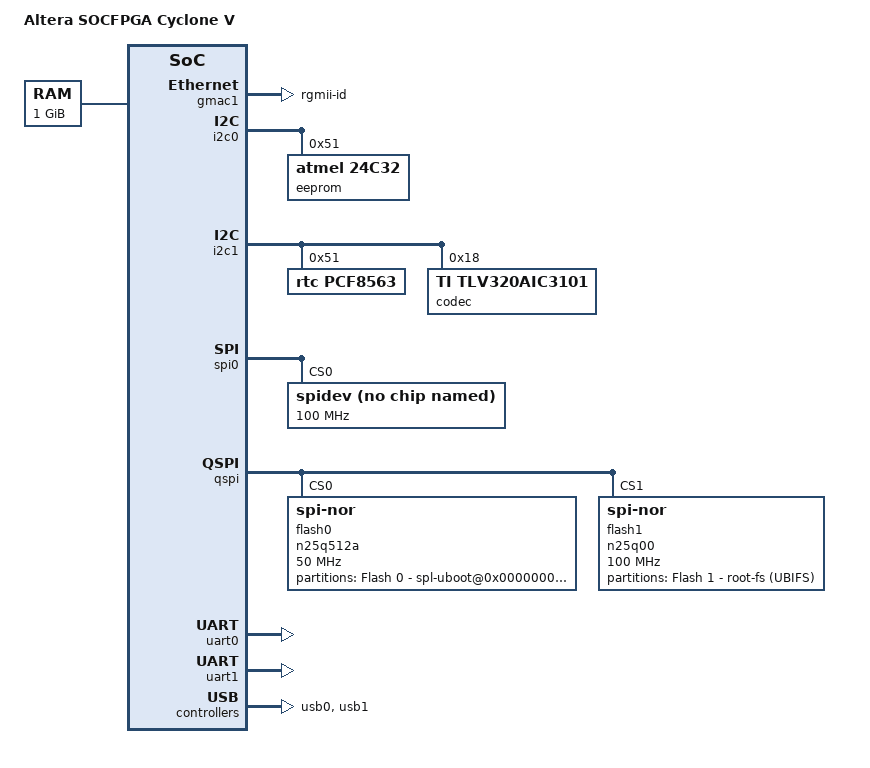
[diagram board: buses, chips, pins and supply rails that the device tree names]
/*
 * This devicetree is originally generated by sopc2dts version 15.1 and modified to by hand to support the blackhawk target.
 * Sopc2dts is written by Walter Goossens <waltergoossens@home.nl>
 * in cooperation with the nios2 community <nios2-dev@lists.rocketboards.org>
 */
#include "socfpga_cyclone5.dtsi"

/ {
	model = "Altera SOCFPGA Cyclone V";	
	compatible = "altr,socfpga-cyclone5", "altr,socfpga";

	chosen {
		bootargs = "earlyprintk";
		stdout-path = "serial0:115200n8";
	};

	memory {
		name = "memory";
		device_type = "memory";
		reg = <0x00000000 0x40000000>;
	};

	aliases {
		serial0 = "&uart0";
		serial1 = "&uart1";
		serial2 = "&uart2";
		serial3 = "&uart3";
		serial4 = "&uart4";
		serial5 = "&uart5";
		spi0 = "&spi0";
		ethernet0 = &gmac1;
	};

	soc {
	};
};

&base_fpga_region {
	#address-cells = <1>;
	#size-cells = <1>;
	ranges = <0 0xff200000 0x00200000>;
	fpga-bridges = <&fpga_bridge0>;

	external-fpga-config;

	Nighthawk_FPGA_IO_alt_vip_vfr_0: vip@0xff244000 {
		compatible = "ALTR,vip-frame-reader-14.0", "ALTR,vip-frame-reader-9.1";
		reg = < 0x00044000 0x00000080 >;
		interrupt-parent = < &intc >;
		interrupts = < 0 43 4 >;
		clocks = <&h2f_user0_clk>,  <&h2f_user0_clk>;
		clock-names = "clock_reset", "clock_master";
		max-width = < 640 >;      /* MAX_IMAGE_WIDTH type NUMBER */
		max-height = < 480 >;     /* MAX_IMAGE_HEIGHT type NUMBER */
		bits-per-color = < 8 >;   /* BITS_PER_PIXEL_PER_COLOR_PLANE type NUMBER */
		colors-per-beat = < 4 >;  /* NUMBER_OF_CHANNELS_IN_PARALLEL type NUMBER */
		beats-per-pixel = < 1 >;  /* NUMBER_OF_CHANNELS_IN_SEQUENCE type NUMBER */
		mem-word-width = < 128 >; /* MEM_PORT_WIDTH type NUMBER */
	};

};

&gmac1 {
	status = "okay";
	phy-mode = "rgmii-id";
	snps,phy-addr = < 0xFFFFFFFF >;
	phy-addr = < 0xFFFFFFFF >;

	rxd0-skew-ps = <0>;
	rxd1-skew-ps = <0>;
	rxd2-skew-ps = <0>;
	rxd3-skew-ps = <0>;
	txd0-skew-ps = <0>;
	txd1-skew-ps = <0>;
	txd2-skew-ps = <0>;
	txd3-skew-ps = <0>;
	txen-skew-ps = <0>;
	txc-skew-ps = <3000>;
	rxdv-skew-ps = <0>;
	rxc-skew-ps = <3000>;
	max-frame-size = <3800>;
	tx-fifo-depth = <4096>;
	rx-fifo-depth = <4096>;
};

&i2c0 {
	status = "ok";
	speed-mode = <0>;

	eeprom@51 {
		compatible = "atmel,24c32";
		reg = < 0x00000051 >;
		pagesize = < 32 >;	/* appended from boardinfo */
	}; //end atmel,24c32@0x51 (eeprom)
};

&i2c1 {
	status = "okay";
	speed-mode = <0>;

	rtc@51 {
		compatible = "rtc,pcf8563";
		reg = <0x51>;
	};
};

&i2c1 {
	status = "okay";
	speed-mode = <0>;

	codec@18 {
		compatible = "TI,TLV320AIC3101";
		reg = < 0x00000018 >;
	};
};

&spi0 {
	#address-cells = < 1 >;
	#size-cells = < 0 >;
	bus-num = < 0 >;
	num-chipselect = < 4 >;
	status = "okay";

	spidev@0 {
		compatible = "spidev";
		reg = < 0 >;
		spi-max-frequency = < 100000000 >;
		enable-dma = < 1 >;
	};
};

&qspi {
	status = "okay";
	flash0: n25q512a@0 {
		#address-cells = <1>;
		#size-cells = <1>;
		compatible = "jedec,spi-nor";
		reg = <0>;
		spi-max-frequency = <50000000>;

		cdns,page-size = <256>;
		cdns,block-size = <16>;
		cdns,read-delay = <4>;
		cdns,tshsl-ns = <50>;
		cdns,tsd2d-ns = <50>;
		cdns,tchsh-ns = <4>;
		cdns,tslch-ns = <4>;

		part0: partition@0 {
			label = "Flash 0 - spl-uboot@0x0000000 / zImage@0xA000000";
			reg = <0x00 0x800000>;
		};

		part1: partition@800000 {
			label = "Flash 0 - not used";
			reg = <0x800000 0x3000000>;
		};

		part2: partition@3800000 {
			label = "Flash 0 - FPGA Image";
			reg = <0x3800000 0x600000>;
		};

		part3: partition@3e00000 {
			label = "Flash 0 - Splash Screen Image";
			reg = <0x3e00000 0x200000>;
		};
	};

	flash1: n25q00@1 {
		#address-cells = <1>;
		#size-cells = <1>;
		compatible = "jedec,spi-nor";
		reg = <1>;
		spi-max-frequency = <100000000>;
		cdns,page-size = <256>;
		cdns,block-size = <16>;
		cdns,read-delay = <4>;
		cdns,tshsl-ns = <50>;
		cdns,tsd2d-ns = <50>;
		cdns,tchsh-ns = <4>;
		cdns,tslch-ns = <4>;

		part4: partition@0 {
			label = "Flash 1 - root-fs (UBIFS)";
			reg = <0x00000000 0x08000000>;
		};
	};
};

&uart0 {
	status = "okay";
	/delete-property/ dmas;
	/delete-property/ dma-names;
};

&uart1 {
	status = "okay";
	/delete-property/ dmas;
	/delete-property/ dma-names;
};

&usbphy0 {
	clocks = < &h2f_user0_clk >;
	clock-names = "main_clk";
};

&usb0 {
	status = "okay";
};

&usb1 {
	status = "okay";
};

&gpio0 {
	status = "okay";
};

&gpio1 {
	status = "okay";
};

&gpio2 {
	status = "okay";
};
